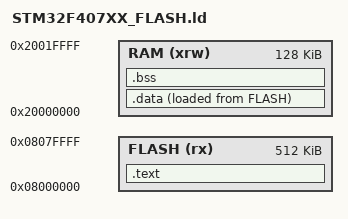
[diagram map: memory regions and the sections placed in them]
ENTRY(Reset_Handler)

MEMORY
{
    FLASH (rx) : ORIGIN = 0x08000000, LENGTH = 512K
    RAM (xrw)  : ORIGIN = 0x20000000, LENGTH = 128K
}

SECTIONS
{
    .text : { *(.text*) *(.rodata*) } > FLASH
    .data : { *(.data*) } > RAM AT > FLASH
    .bss  : { *(.bss*) *(COMMON) } > RAM
}
